VERSION ""

NS_ :

BS_:

BU_: Vector__XXX

BO_ 1552 CONTAINS_LRES_SPEED: 8 Vector__XXX
SG_ SPEED_LOWRES : 16|8@1+ (1,0) [0|255] "km/h?" Vector__XXX
SG_ NEW_SIGNAL_1 : 7|8@0+ (1,0) [0|255] "" Vector__XXX

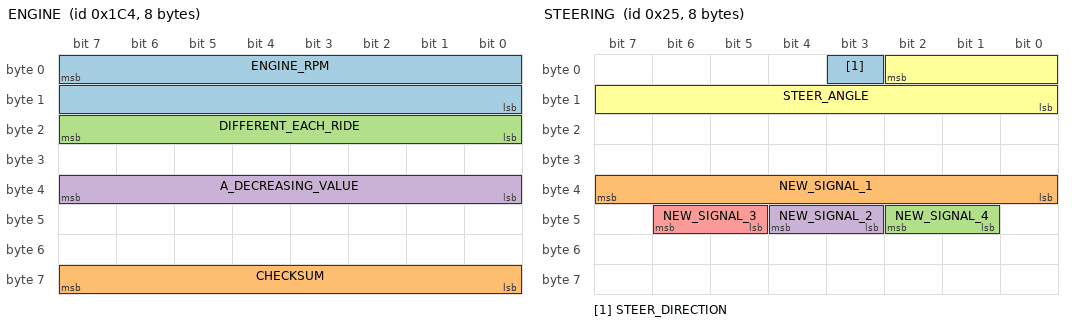
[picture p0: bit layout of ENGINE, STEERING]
BO_ 452 ENGINE: 8 Vector__XXX
SG_ ENGINE_RPM : 7|16@0+ (1,0) [0|65535] "rpm" Vector__XXX
SG_ CHECKSUM : 63|8@0+ (1,0) [0|255] "" Vector__XXX
SG_ DIFFERENT_EACH_RIDE : 23|8@0+ (1,0) [0|255] "" Vector__XXX
SG_ A_DECREASING_VALUE : 39|8@0+ (1,0) [0|255] "" Vector__XXX

BO_ 37 STEERING: 8 Vector__XXX
SG_ STEER_DIRECTION : 3|1@0+ (1,0) [0|1] "" Vector__XXX
SG_ NEW_SIGNAL_1 : 39|8@0+ (1,0) [0|255] "" Vector__XXX
SG_ NEW_SIGNAL_4 : 42|2@0- (1,0) [0|1] "" Vector__XXX
SG_ NEW_SIGNAL_2 : 44|2@0- (1,0) [0|1] "" Vector__XXX
SG_ NEW_SIGNAL_3 : 46|2@0- (1,0) [0|1] "" Vector__XXX
SG_ STEER_ANGLE : 2|11@0- (1,0) [-350|350] "" Vector__XXX

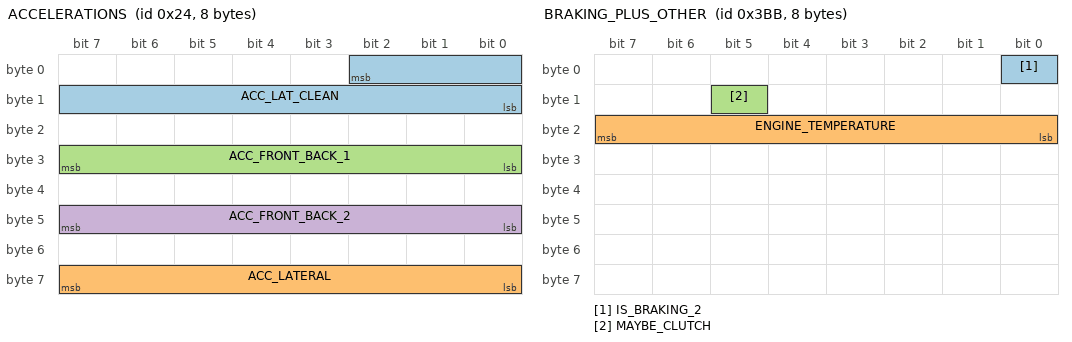
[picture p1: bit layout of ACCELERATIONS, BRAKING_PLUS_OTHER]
BO_ 36 ACCELERATIONS: 8 Vector__XXX
SG_ ACC_LAT_CLEAN : 2|11@0- (1,0) [0|255] "" Vector__XXX
SG_ ACC_LATERAL : 63|8@0- (1,0) [0|127] "" Vector__XXX
SG_ ACC_FRONT_BACK_1 : 31|8@0- (1,0) [0|127] "" Vector__XXX
SG_ ACC_FRONT_BACK_2 : 47|8@0- (1,0) [0|127] "" Vector__XXX

BO_ 947 LOW_RES_INDICATORS: 8 Vector__XXX
SG_ LOW_RES_ACC_PEDAL : 23|7@0+ (1,0) [0|63] "" Vector__XXX
SG_ LOW_RES_RPM : 7|16@0+ (1,0) [0|255] "rpm" Vector__XXX

BO_ 955 BRAKING_PLUS_OTHER: 8 Vector__XXX
SG_ IS_BRAKING_2 : 0|1@0+ (1,0) [0|1] "" Vector__XXX
SG_ ENGINE_TEMPERATURE : 23|8@0+ (1,0) [0|255] "" Vector__XXX
SG_ MAYBE_CLUTCH : 13|1@0+ (1,0) [0|1] "" Vector__XXX

BO_ 1595 CONTAINS_TIME: 8 Vector__XXX
SG_ TIME_ON : 55|16@0+ (0.1,0) [0|6553.5] "s" Vector__XXX
SG_ BETWEEN_RIDES : 7|32@0+ (1,0) [0|4294967295] "" Vector__XXX

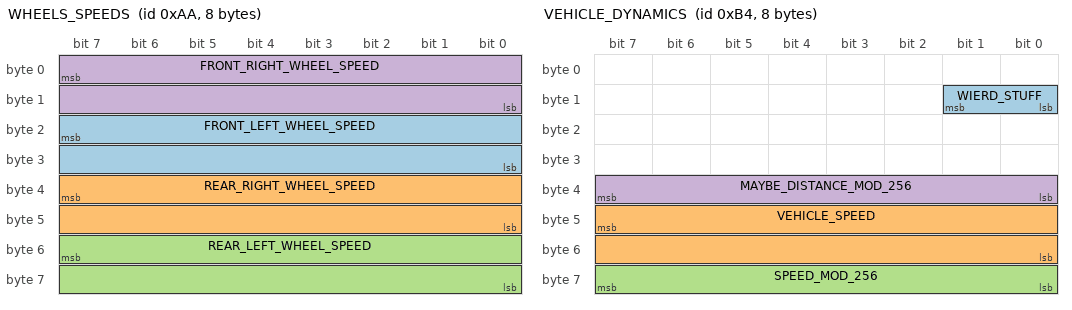
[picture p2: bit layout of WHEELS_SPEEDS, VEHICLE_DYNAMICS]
BO_ 170 WHEELS_SPEEDS: 8 Vector__XXX
SG_ FRONT_LEFT_WHEEL_SPEED : 23|16@0+ (0.01,-67.67) [0|587.68] "km/h" Vector__XXX
SG_ REAR_RIGHT_WHEEL_SPEED : 39|16@0+ (0.01,-67.67) [0|587.68] "km/h" Vector__XXX
SG_ REAR_LEFT_WHEEL_SPEED : 55|16@0+ (0.01,-67.67) [0|587.68] "km/h" Vector__XXX
SG_ FRONT_RIGHT_WHEEL_SPEED : 7|16@0+ (0.01,-67.67) [0|587.68] "km/h" Vector__XXX

BO_ 180 VEHICLE_DYNAMICS: 8 Vector__XXX
SG_ WIERD_STUFF : 8|2@1+ (1,0) [0|3] "" Vector__XXX
SG_ VEHICLE_SPEED : 47|16@0+ (0.01,0) [0|255] "km/h" Vector__XXX
SG_ SPEED_MOD_256 : 63|8@0- (1,0) [0|127] "" Vector__XXX
SG_ MAYBE_DISTANCE_MOD_256 : 39|8@0+ (1,0) [0|255] "" Vector__XXX

BO_ 186 NEW_MSG_9: 8 Vector__XXX
SG_ NEW_SIGNAL_2 : 31|8@0+ (1,0) [0|255] "" Vector__XXX

BO_ 426 NEW_MSG_5: 8 Vector__XXX
SG_ CONSTANT : 47|8@0+ (1,0) [0|255] "" Vector__XXX

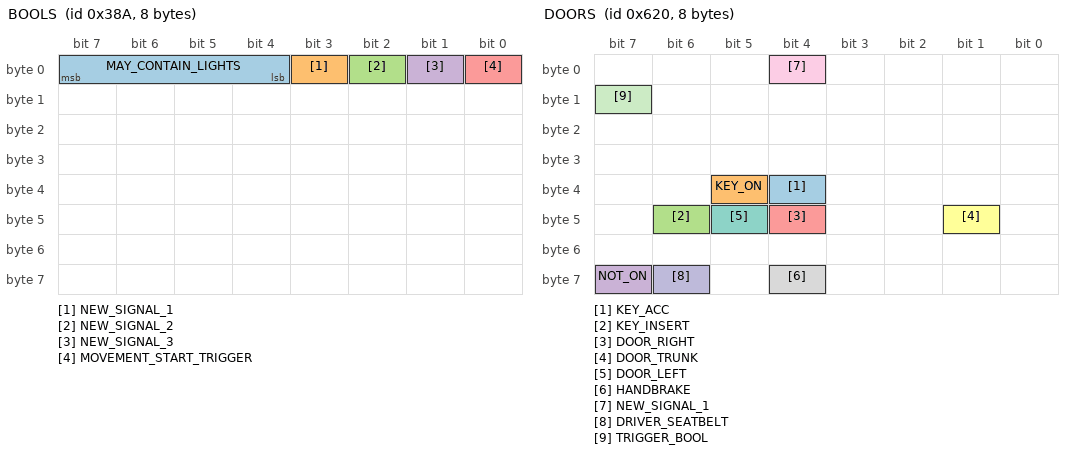
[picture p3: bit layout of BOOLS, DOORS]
BO_ 906 BOOLS: 8 Vector__XXX
SG_ MAY_CONTAIN_LIGHTS : 7|4@0+ (1,0) [0|15] "" Vector__XXX
SG_ NEW_SIGNAL_1 : 3|1@0+ (1,0) [0|1] "" Vector__XXX
SG_ NEW_SIGNAL_2 : 2|1@0+ (1,0) [0|1] "" Vector__XXX
SG_ NEW_SIGNAL_3 : 1|1@0+ (1,0) [0|1] "" Vector__XXX
SG_ MOVEMENT_START_TRIGGER : 0|1@0+ (1,0) [0|1] "" Vector__XXX

BO_ 979 LOW_RES_ACCELERATOR: 8 Vector__XXX
SG_ VERY_LRES_ACC : 7|16@0+ (1,0) [0|65535] "" Vector__XXX

BO_ 1600 SLOW_VARIABLE_INFOS: 8 Vector__XXX
SG_ CHANGES_EACH_RIDE : 31|8@0+ (1,0) [0|255] "" Vector__XXX
SG_ INCREASING_VALUE_FUEL : 47|8@0+ (1,0) [0|255] "" Vector__XXX

BO_ 1568 DOORS: 8 Vector__XXX
SG_ KEY_ACC : 36|1@0+ (1,0) [0|1] "" Vector__XXX
SG_ KEY_ON : 37|1@0+ (1,0) [0|1] "" Vector__XXX
SG_ KEY_INSERT : 46|1@0+ (1,0) [0|1] "" Vector__XXX
SG_ NOT_ON : 63|1@0+ (1,0) [0|1] "" Vector__XXX
SG_ DOOR_RIGHT : 44|1@0+ (1,0) [0|1] "" Vector__XXX
SG_ DOOR_TRUNK : 41|1@1+ (1,0) [0|1] "" Vector__XXX
SG_ DOOR_LEFT : 45|1@0+ (1,0) [0|1] "" Vector__XXX
SG_ HANDBRAKE : 60|1@0+ (1,0) [0|1] "" Vector__XXX
SG_ NEW_SIGNAL_1 : 4|1@0+ (1,0) [0|1] "" Vector__XXX
SG_ DRIVER_SEATBELT : 62|1@0+ (1,0) [0|1] "" Vector__XXX
SG_ TRIGGER_BOOL : 15|1@0+ (1,0) [0|1] "" Vector__XXX

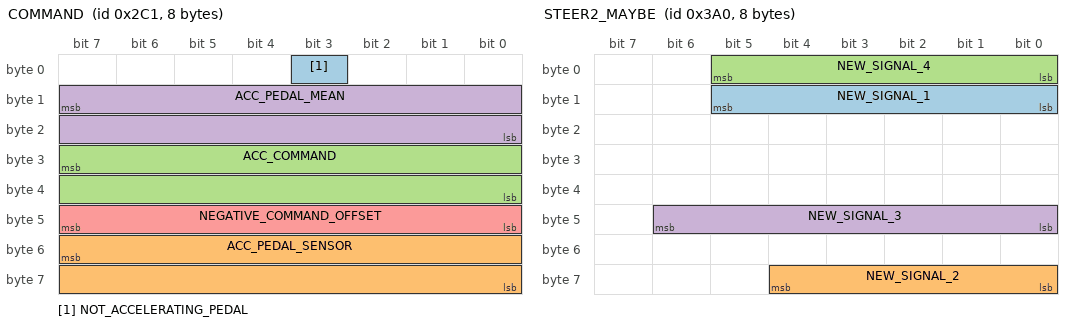
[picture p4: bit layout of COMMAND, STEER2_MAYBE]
BO_ 705 COMMAND: 8 Vector__XXX
SG_ NOT_ACCELERATING_PEDAL : 3|1@1+ (1,0) [0|1] "" Vector__XXX
SG_ ACC_PEDAL_SENSOR : 55|16@0+ (1,0) [0|65535] "" Vector__XXX
SG_ ACC_COMMAND : 31|16@0- (1,0) [0|7] "" Vector__XXX
SG_ ACC_PEDAL_MEAN : 15|16@0- (1,0) [0|255] "" Vector__XXX
SG_ NEGATIVE_COMMAND_OFFSET : 47|8@0- (1,0) [0|127] "" Vector__XXX

BO_ 928 STEER2_MAYBE: 8 Vector__XXX
SG_ NEW_SIGNAL_1 : 13|6@0+ (1,0) [0|63] "" Vector__XXX
SG_ NEW_SIGNAL_2 : 60|5@0+ (1,0) [0|31] "" Vector__XXX
SG_ NEW_SIGNAL_4 : 5|6@0+ (1,0) [0|63] "" Vector__XXX
SG_ NEW_SIGNAL_3 : 46|7@0+ (1,0) [0|15] "" Vector__XXX

BO_ 896 LONG_TERM_2: 8 Vector__XXX
SG_ NEW_SIGNAL_1 : 55|8@0+ (1,0) [0|255] "" Vector__XXX

BO_ 944 LONG_TERM_MSG: 8 Vector__XXX
SG_ LONG_TERM_SIGN : 31|8@0+ (1,0) [0|255] "" Vector__XXX

BO_ 1553 TOTAL_DIST: 8 Vector__XXX
SG_ TOTAL_DISTANCE : 55|16@0+ (1,0) [0|65535] "" Vector__XXX

BO_ 1572 WHY_THESE_VALUES: 8 Vector__XXX

BO_ 1555 BETWEEN_RIDES_CHANGE_1: 8 Vector__XXX
SG_ BETWEEN_RIDES : 23|1@0+ (1,0) [0|1] "" Vector__XXX

BO_ 1090 ASYNC_MSG_ACK: 8 Vector__XXX
SG_ NEW_SIGNAL_1 : 13|2@0+ (1,0) [0|1] "" Vector__XXX
SG_ NEW_SIGNAL_2 : 23|1@0+ (1,0) [0|1] "" Vector__XXX

BO_ 1592 NEW_MSG_14: 8 Vector__XXX
SG_ DOORS_LOCKED2 : 20|1@0+ (1,0) [0|1] "" Vector__XXX
SG_ DOORS_LOCKED1 : 16|1@0+ (1,0) [0|1] "" Vector__XXX

BO_ 608 NEW_MSG_6: 8 Vector__XXX
SG_ VERY_SMALL_SIGNAL2 : 56|1@0+ (1,0) [0|1] "" Vector__XXX
SG_ VERY_SMALL_SIGNAL1 : 0|1@0+ (1,0) [0|1] "" Vector__XXX

BO_ 945 BETWEEN_RIDES_CHANGES_2: 8 Vector__XXX
SG_ BETWEEN_RIDES : 24|1@0+ (1,0) [0|1] "" Vector__XXX

CM_ SG_ 1552 SPEED_LOWRES "Negative values to check";
CM_ SG_ 452 CHECKSUM "Follows path of RPMs but more precise & 1 byte only";
CM_ SG_ 452 A_DECREASING_VALUE "stabilizes to 62 after ~10 mins";
CM_ SG_ 37 STEER_DIRECTION "Could be intended as 12 bit steering angle";
CM_ SG_ 37 STEER_ANGLE "can convert to degrees (imprecise) or percentage of max amplitude";
CM_ SG_ 36 ACC_FRONT_BACK_1 "more likely up-down";
CM_ SG_ 36 ACC_FRONT_BACK_2 "more likely front-back";
CM_ SG_ 947 LOW_RES_ACC_PEDAL "Follows rather closely other acceleration commands";
CM_ SG_ 947 LOW_RES_RPM "Maybe used for onboard display?";
CM_ SG_ 955 MAYBE_CLUTCH "might be related to shifting gears";
CM_ SG_ 1595 TIME_ON "Time since last ignition, tenth of seconds";
CM_ SG_ 1595 BETWEEN_RIDES "the fourth byte (at least) changes between rides";
CM_ SG_ 180 WIERD_STUFF "Might be a signed value on the whole two bytes (sometimes all set)";
CM_ SG_ 180 VEHICLE_SPEED "Roughly 2 seconds before wheel speeds";
CM_ SG_ 180 SPEED_MOD_256 "One byte speed, a bit before vehicle speed";
CM_ SG_ 180 MAYBE_DISTANCE_MOD_256 "Looks like measure for distance or wheel angle";
CM_ SG_ 906 MOVEMENT_START_TRIGGER "trigger of when speed becomes != 0";
CM_ SG_ 979 VERY_LRES_ACC "Power used by engine? moves alongside speed, very low res, goes from 0 to 9 max?";
CM_ SG_ 1600 CHANGES_EACH_RIDE "Small decrementation during some rides, possibly long term fuel";
CM_ SG_ 1600 INCREASING_VALUE_FUEL "Fuel/distance? Average fuel consumption?";
CM_ SG_ 705 NOT_ACCELERATING_PEDAL "Looks like opposite of accelerating bit";
CM_ SG_ 705 ACC_PEDAL_SENSOR "similar to pedal sensor maybe checksum.";
CM_ SG_ 705 ACC_COMMAND "Similar to other pedal indicator., cleaner, must be sent back to engine";
CM_ SG_ 705 ACC_PEDAL_MEAN "Actual sensor for pedal (works when engine off)";
CM_ SG_ 705 NEGATIVE_COMMAND_OFFSET "Mysterious for now";
CM_ SG_ 928 NEW_SIGNAL_1 "Very slow changing noisy value, 45-49 in 10 min";
CM_ SG_ 928 NEW_SIGNAL_2 "Other very slow changing 24-26 in 10 min";
CM_ SG_ 928 NEW_SIGNAL_4 "Inconsistent across rides";
CM_ SG_ 896 NEW_SIGNAL_1 "there is a difference at the beginning of 2017-10-31--12-04-05";
CM_ SG_ 1553 TOTAL_DISTANCE "Probably also contains the previous/two previous bytes but can't confirm";
CM_ SG_ 945 BETWEEN_RIDES "Might be others in the same message. at least this one";

BA_DEF_  "BusType" STRING ;

BA_DEF_DEF_  "BusType" "CAN";
